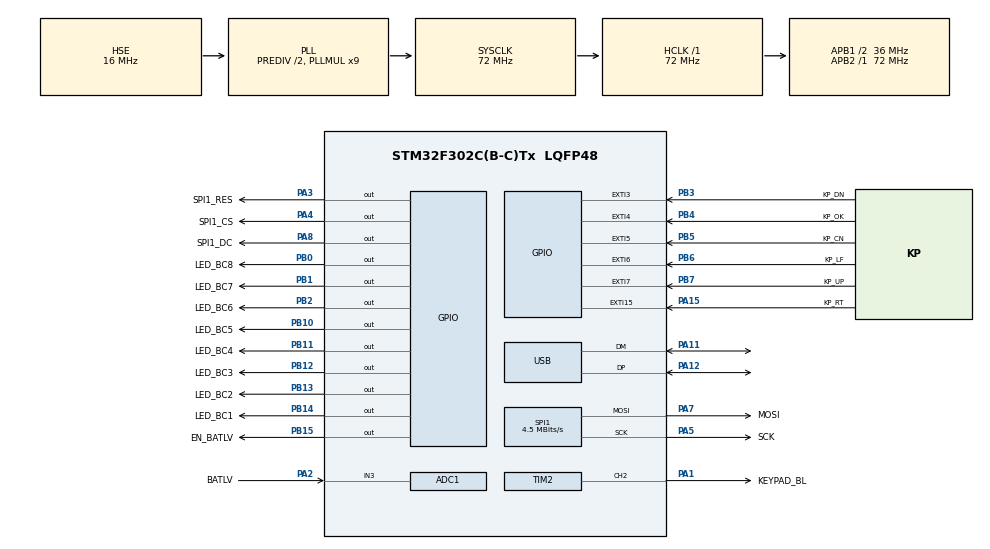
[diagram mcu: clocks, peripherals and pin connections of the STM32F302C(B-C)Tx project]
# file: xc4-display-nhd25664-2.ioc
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ADC1.Channel-1\#ChannelRegularConversion=ADC_CHANNEL_3
ADC1.NbrOfConversionFlag=1
ADC1.Offset-1\#ChannelRegularConversion=0
ADC1.OffsetNumber-1\#ChannelRegularConversion=ADC_OFFSET_NONE
ADC1.Rank-1\#ChannelRegularConversion=1
ADC1.SamplingTime-1\#ChannelRegularConversion=ADC_SAMPLETIME_1CYCLE_5
ADC1.master=1
Mcu.Family=STM32F3
Mcu.Name=STM32F302C(B-C)Tx
Mcu.Package=LQFP48
NVIC.EXTI15_10_IRQn=true\:1\:1\:true\:false\:true\:true\:true\:true
NVIC.EXTI3_IRQn=true\:1\:1\:true\:false\:true\:true\:true\:true
NVIC.EXTI4_IRQn=true\:1\:1\:true\:false\:true\:true\:true\:true
NVIC.EXTI9_5_IRQn=true\:1\:1\:true\:false\:true\:true\:true\:true
NVIC.PriorityGroup=NVIC_PRIORITYGROUP_3
NVIC.RCC_IRQn=true\:1\:0\:true\:false\:true\:true\:false\:true
NVIC.TIM2_IRQn=true\:1\:0\:true\:false\:true\:true\:true\:true
NVIC.TIM3_IRQn=true\:0\:0\:false\:false\:true\:true\:true\:true
NVIC.TIM4_IRQn=true\:0\:0\:false\:false\:true\:true\:true\:true
NVIC.USB_HP_CAN_TX_IRQn=true\:0\:0\:false\:false\:true\:true\:true\:true
NVIC.USB_LP_CAN_RX0_IRQn=true\:0\:1\:false\:false\:true\:true\:true\:true
PA1.GPIO_Label=KEYPAD_BL
PA1.Signal=S_TIM2_CH2
PA11.Mode=Device
PA11.Signal=USB_DM
PA12.Mode=Device
PA12.Signal=USB_DP
PA13.Mode=Serial_Wire
PA13.Signal=SYS_JTMS-SWDIO
PA14.Mode=Serial_Wire
PA14.Signal=SYS_JTCK-SWCLK
PA15.GPIO_Label=KP_RT
PA15.GPIO_ModeDefaultEXTI=GPIO_MODE_IT_FALLING
PA15.GPIO_PuPd=GPIO_PULLUP
PA15.Signal=GPXTI15
PA2.GPIO_Label=BATLV
PA2.Mode=IN3-Single-Ended
PA2.Signal=ADC1_IN3
PA3.GPIO_Label=SPI1_RES
PA3.Signal=GPIO_Output
PA4.GPIO_Label=SPI1_CS
PA4.Signal=GPIO_Output
PA5.GPIO_Label=SCK
PA5.Mode=TX_Only_Simplex_Unidirect_Master
PA5.Signal=SPI1_SCK
PA7.GPIO_Label=MOSI
PA7.Mode=TX_Only_Simplex_Unidirect_Master
PA7.Signal=SPI1_MOSI
PA8.GPIO_Label=SPI1_DC
PA8.Signal=GPIO_Output
PB0.GPIO_Label=LED_BC8
PB0.Signal=GPIO_Output
PB1.GPIO_Label=LED_BC7
PB1.Signal=GPIO_Output
PB10.GPIO_Label=LED_BC5
PB10.Signal=GPIO_Output
PB11.GPIO_Label=LED_BC4
PB11.Signal=GPIO_Output
PB12.GPIO_Label=LED_BC3
PB12.Signal=GPIO_Output
PB13.GPIO_Label=LED_BC2
PB13.Signal=GPIO_Output
PB14.GPIO_Label=LED_BC1
PB14.Signal=GPIO_Output
PB15.GPIO_Label=EN_BATLV
PB15.Signal=GPIO_Output
PB2.GPIO_Label=LED_BC6
PB2.Signal=GPIO_Output
PB3.GPIO_Label=KP_DN
PB3.GPIO_ModeDefaultEXTI=GPIO_MODE_IT_FALLING
PB3.GPIO_PuPd=GPIO_PULLUP
PB3.Signal=GPXTI3
PB4.GPIO_Label=KP_OK
PB4.GPIO_ModeDefaultEXTI=GPIO_MODE_IT_FALLING
PB4.GPIO_PuPd=GPIO_PULLUP
PB4.Signal=GPXTI4
PB5.GPIO_Label=KP_CN
PB5.GPIO_ModeDefaultEXTI=GPIO_MODE_IT_FALLING
PB5.GPIO_PuPd=GPIO_PULLUP
PB5.Signal=GPXTI5
PB6.GPIO_Label=KP_LF
PB6.GPIO_ModeDefaultEXTI=GPIO_MODE_IT_FALLING
PB6.GPIO_PuPd=GPIO_PULLUP
PB6.Signal=GPXTI6
PB7.GPIO_Label=KP_UP
PB7.GPIO_ModeDefaultEXTI=GPIO_MODE_IT_FALLING
PB7.GPIO_PuPd=GPIO_PULLUP
PB7.Signal=GPXTI7
PF0-OSC_IN.Mode=HSE-External-Oscillator
PF0-OSC_IN.Signal=RCC_OSC_IN
PF1-OSC_OUT.Mode=HSE-External-Oscillator
PF1-OSC_OUT.Signal=RCC_OSC_OUT
ProjectManager.HeapSize=0x200
ProjectManager.StackSize=0x400
ProjectManager.TargetToolchain=STM32CubeIDE
RCC.AHBFreq_Value=72000000
RCC.APB1CLKDivider=RCC_HCLK_DIV2
RCC.APB1Freq_Value=36000000
RCC.APB1TimFreq_Value=72000000
RCC.APB2Freq_Value=72000000
RCC.APB2TimFreq_Value=72000000
RCC.CortexFreq_Value=72000000
RCC.HCLKFreq_Value=72000000
RCC.HSE_VALUE=16000000
RCC.HSI_VALUE=8000000
RCC.LSE_VALUE=32768
RCC.PLLMUL=RCC_PLL_MUL9
RCC.PRESCALERUSB=RCC_USBCLKSOURCE_PLL_DIV1_5
RCC.RCC_PLLsource_Clock_Source_FROM_HSE=RCC_HSE_PREDIV_DIV2
RCC.SYSCLKFreq_VALUE=72000000
RCC.SYSCLKSourceVirtual=RCC_SYSCLKSOURCE_PLLCLK
RCC.USBFreq_Value=48000000
SH.S_TIM2_CH2.0=TIM2_CH2,PWM Generation2 CH2
SPI1.BaudRatePrescaler=SPI_BAUDRATEPRESCALER_16
SPI1.CalculateBaudRate=4.5 MBits/s
SPI1.DataSize=SPI_DATASIZE_8BIT
SPI1.Direction=SPI_DIRECTION_2LINES
SPI1.Mode=SPI_MODE_MASTER
SPI1.VirtualType=VM_MASTER
TIM2.AutoReloadPreload=TIM_AUTORELOAD_PRELOAD_ENABLE
TIM2.Channel-PWM\ Generation2\ CH2=TIM_CHANNEL_2
TIM2.Period=65535
TIM2.Prescaler=0
TIM2.Pulse-PWM\ Generation2\ CH2=0
TIM3.Period=30
TIM3.Prescaler=60000
TIM4.Period=64999
TIM4.Prescaler=5499
USB_DEVICE.CLASS_NAME_FS=CDC
USB_DEVICE.MANUFACTURER_STRING=Viacast
USB_DEVICE.PID_CDC_FS=0x2303
USB_DEVICE.PRODUCT_STRING_CDC_FS=USB Nano Display
USB_DEVICE.USBD_SELF_POWERED=0
USB_DEVICE.VID=0x067B
USB_DEVICE.VirtualMode=Cdc
USB_DEVICE.VirtualModeFS=Cdc_FS
VP_TIM2_VS_ClockSourceINT.Mode=Internal
VP_TIM3_VS_ClockSourceINT.Mode=Internal
VP_TIM4_VS_ClockSourceINT.Mode=Internal
VP_USB_DEVICE_VS_USB_DEVICE_CDC_FS.Mode=CDC_FS
board=custom

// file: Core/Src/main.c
/* USER CODE BEGIN Header */
/**
  ******************************************************************************
  * @file           : main.c
  * @brief          : Main program body
  ******************************************************************************
  * @attention
  *
  * Copyright (c) 2022 STMicroelectronics.
  * All rights reserved.
  *
  * This software is licensed under terms that can be found in the LICENSE file
  * in the root directory of this software component.
  * If no LICENSE file comes with this software, it is provided AS-IS.
  *
  ******************************************************************************
  */
/* USER CODE END Header */
#include "main.h"
#include "usb_device.h"

/* USER CODE BEGIN Includes */
#include "ac.h"
/* USER CODE END Includes */

ADC_HandleTypeDef hadc1;

SPI_HandleTypeDef hspi1;

TIM_HandleTypeDef htim2;
TIM_HandleTypeDef htim3;
TIM_HandleTypeDef htim4;

void SystemClock_Config(void);
static void MX_GPIO_Init(void);
static void MX_SPI1_Init(void);
static void MX_ADC1_Init(void);
static void MX_TIM2_Init(void);
static void MX_TIM3_Init(void);
static void MX_TIM4_Init(void);

int main(void)
{

  /* MCU Configuration--------------------------------------------------------*/

  /* Reset of all peripherals, Initializes the Flash interface and the Systick. */
  HAL_Init();

  /* Configure the system clock */
  SystemClock_Config();

  /* Initialize all configured peripherals */
  MX_GPIO_Init();
  MX_SPI1_Init();
  MX_ADC1_Init();
  MX_TIM2_Init();
  MX_USB_DEVICE_Init();
  MX_TIM3_Init();
  MX_TIM4_Init();
  /* USER CODE BEGIN 2 */
  start_app();
  /* USER CODE END 2 */

  /* Infinite loop */
  /* USER CODE BEGIN WHILE */
  while (1)
  {
	  __WFI();
    /* USER CODE END WHILE */

  }
}

void SystemClock_Config(void)
{
  RCC_OscInitTypeDef RCC_OscInitStruct = {0};
  RCC_ClkInitTypeDef RCC_ClkInitStruct = {0};
  RCC_PeriphCLKInitTypeDef PeriphClkInit = {0};

  /** Initializes the RCC Oscillators according to the specified parameters
  * in the RCC_OscInitTypeDef structure.
  */
  RCC_OscInitStruct.OscillatorType = RCC_OSCILLATORTYPE_HSE;
  RCC_OscInitStruct.HSEState = RCC_HSE_ON;
  RCC_OscInitStruct.HSEPredivValue = RCC_HSE_PREDIV_DIV2;
  RCC_OscInitStruct.HSIState = RCC_HSI_ON;
  RCC_OscInitStruct.PLL.PLLState = RCC_PLL_ON;
  RCC_OscInitStruct.PLL.PLLSource = RCC_PLLSOURCE_HSE;
  RCC_OscInitStruct.PLL.PLLMUL = RCC_PLL_MUL9;
  if (HAL_RCC_OscConfig(&RCC_OscInitStruct) != HAL_OK)
  {
    Error_Handler();
  }

  /** Initializes the CPU, AHB and APB buses clocks
  */
  RCC_ClkInitStruct.ClockType = RCC_CLOCKTYPE_HCLK|RCC_CLOCKTYPE_SYSCLK
                              |RCC_CLOCKTYPE_PCLK1|RCC_CLOCKTYPE_PCLK2;
  RCC_ClkInitStruct.SYSCLKSource = RCC_SYSCLKSOURCE_PLLCLK;
  RCC_ClkInitStruct.AHBCLKDivider = RCC_SYSCLK_DIV1;
  RCC_ClkInitStruct.APB1CLKDivider = RCC_HCLK_DIV2;
  RCC_ClkInitStruct.APB2CLKDivider = RCC_HCLK_DIV1;

  if (HAL_RCC_ClockConfig(&RCC_ClkInitStruct, FLASH_LATENCY_2) != HAL_OK)
  {
    Error_Handler();
  }
  PeriphClkInit.PeriphClockSelection = RCC_PERIPHCLK_USB|RCC_PERIPHCLK_ADC12;
  PeriphClkInit.Adc12ClockSelection = RCC_ADC12PLLCLK_DIV1;
  PeriphClkInit.USBClockSelection = RCC_USBCLKSOURCE_PLL_DIV1_5;
  if (HAL_RCCEx_PeriphCLKConfig(&PeriphClkInit) != HAL_OK)
  {
    Error_Handler();
  }
}

static void MX_ADC1_Init(void)
{

  ADC_MultiModeTypeDef multimode = {0};
  ADC_ChannelConfTypeDef sConfig = {0};

  /** Common config
  */
  hadc1.Instance = ADC1;
  hadc1.Init.ClockPrescaler = ADC_CLOCK_ASYNC_DIV1;
  hadc1.Init.Resolution = ADC_RESOLUTION_12B;
  hadc1.Init.ScanConvMode = ADC_SCAN_DISABLE;
  hadc1.Init.ContinuousConvMode = DISABLE;
  hadc1.Init.DiscontinuousConvMode = DISABLE;
  hadc1.Init.ExternalTrigConvEdge = ADC_EXTERNALTRIGCONVEDGE_NONE;
  hadc1.Init.ExternalTrigConv = ADC_SOFTWARE_START;
  hadc1.Init.DataAlign = ADC_DATAALIGN_RIGHT;
  hadc1.Init.NbrOfConversion = 1;
  hadc1.Init.DMAContinuousRequests = DISABLE;
  hadc1.Init.EOCSelection = ADC_EOC_SINGLE_CONV;
  hadc1.Init.LowPowerAutoWait = DISABLE;
  hadc1.Init.Overrun = ADC_OVR_DATA_OVERWRITTEN;
  if (HAL_ADC_Init(&hadc1) != HAL_OK)
  {
    Error_Handler();
  }

  /** Configure the ADC multi-mode
  */
  multimode.Mode = ADC_MODE_INDEPENDENT;
  if (HAL_ADCEx_MultiModeConfigChannel(&hadc1, &multimode) != HAL_OK)
  {
    Error_Handler();
  }

  /** Configure Regular Channel
  */
  sConfig.Channel = ADC_CHANNEL_3;
  sConfig.Rank = ADC_REGULAR_RANK_1;
  sConfig.SingleDiff = ADC_SINGLE_ENDED;
  sConfig.SamplingTime = ADC_SAMPLETIME_1CYCLE_5;
  sConfig.OffsetNumber = ADC_OFFSET_NONE;
  sConfig.Offset = 0;
  if (HAL_ADC_ConfigChannel(&hadc1, &sConfig) != HAL_OK)
  {
    Error_Handler();
  }

}

static void MX_SPI1_Init(void)
{

  /* SPI1 parameter configuration*/
  hspi1.Instance = SPI1;
  hspi1.Init.Mode = SPI_MODE_MASTER;
  hspi1.Init.Direction = SPI_DIRECTION_2LINES;
  hspi1.Init.DataSize = SPI_DATASIZE_8BIT;
  hspi1.Init.CLKPolarity = SPI_POLARITY_LOW;
  hspi1.Init.CLKPhase = SPI_PHASE_1EDGE;
  hspi1.Init.NSS = SPI_NSS_SOFT;
  hspi1.Init.BaudRatePrescaler = SPI_BAUDRATEPRESCALER_16;
  hspi1.Init.FirstBit = SPI_FIRSTBIT_MSB;
  hspi1.Init.TIMode = SPI_TIMODE_DISABLE;
  hspi1.Init.CRCCalculation = SPI_CRCCALCULATION_DISABLE;
  hspi1.Init.CRCPolynomial = 7;
  hspi1.Init.CRCLength = SPI_CRC_LENGTH_DATASIZE;
  hspi1.Init.NSSPMode = SPI_NSS_PULSE_ENABLE;
  if (HAL_SPI_Init(&hspi1) != HAL_OK)
  {
    Error_Handler();
  }

}

static void MX_TIM2_Init(void)
{

  TIM_ClockConfigTypeDef sClockSourceConfig = {0};
  TIM_MasterConfigTypeDef sMasterConfig = {0};
  TIM_OC_InitTypeDef sConfigOC = {0};

  htim2.Instance = TIM2;
  htim2.Init.Prescaler = 0;
  htim2.Init.CounterMode = TIM_COUNTERMODE_UP;
  htim2.Init.Period = 65535;
  htim2.Init.ClockDivision = TIM_CLOCKDIVISION_DIV1;
  htim2.Init.AutoReloadPreload = TIM_AUTORELOAD_PRELOAD_ENABLE;
  if (HAL_TIM_Base_Init(&htim2) != HAL_OK)
  {
    Error_Handler();
  }
  sClockSourceConfig.ClockSource = TIM_CLOCKSOURCE_INTERNAL;
  if (HAL_TIM_ConfigClockSource(&htim2, &sClockSourceConfig) != HAL_OK)
  {
    Error_Handler();
  }
  if (HAL_TIM_PWM_Init(&htim2) != HAL_OK)
  {
    Error_Handler();
  }
  sMasterConfig.MasterOutputTrigger = TIM_TRGO_RESET;
  sMasterConfig.MasterSlaveMode = TIM_MASTERSLAVEMODE_DISABLE;
  if (HAL_TIMEx_MasterConfigSynchronization(&htim2, &sMasterConfig) != HAL_OK)
  {
    Error_Handler();
  }
  sConfigOC.OCMode = TIM_OCMODE_PWM1;
  sConfigOC.Pulse = 0;
  sConfigOC.OCPolarity = TIM_OCPOLARITY_HIGH;
  sConfigOC.OCFastMode = TIM_OCFAST_DISABLE;
  if (HAL_TIM_PWM_ConfigChannel(&htim2, &sConfigOC, TIM_CHANNEL_2) != HAL_OK)
  {
    Error_Handler();
  }
  HAL_TIM_MspPostInit(&htim2);

}

static void MX_TIM3_Init(void)
{

  TIM_ClockConfigTypeDef sClockSourceConfig = {0};
  TIM_MasterConfigTypeDef sMasterConfig = {0};

  htim3.Instance = TIM3;
  htim3.Init.Prescaler = 60000;
  htim3.Init.CounterMode = TIM_COUNTERMODE_UP;
  htim3.Init.Period = 30;
  htim3.Init.ClockDivision = TIM_CLOCKDIVISION_DIV1;
  htim3.Init.AutoReloadPreload = TIM_AUTORELOAD_PRELOAD_DISABLE;
  if (HAL_TIM_Base_Init(&htim3) != HAL_OK)
  {
    Error_Handler();
  }
  sClockSourceConfig.ClockSource = TIM_CLOCKSOURCE_INTERNAL;
  if (HAL_TIM_ConfigClockSource(&htim3, &sClockSourceConfig) != HAL_OK)
  {
    Error_Handler();
  }
  sMasterConfig.MasterOutputTrigger = TIM_TRGO_RESET;
  sMasterConfig.MasterSlaveMode = TIM_MASTERSLAVEMODE_DISABLE;
  if (HAL_TIMEx_MasterConfigSynchronization(&htim3, &sMasterConfig) != HAL_OK)
  {
    Error_Handler();
  }

}

static void MX_TIM4_Init(void)
{

  TIM_ClockConfigTypeDef sClockSourceConfig = {0};
  TIM_MasterConfigTypeDef sMasterConfig = {0};

  htim4.Instance = TIM4;
  htim4.Init.Prescaler = 5499;
  htim4.Init.CounterMode = TIM_COUNTERMODE_UP;
  htim4.Init.Period = 64999;
  htim4.Init.ClockDivision = TIM_CLOCKDIVISION_DIV1;
  htim4.Init.AutoReloadPreload = TIM_AUTORELOAD_PRELOAD_DISABLE;
  if (HAL_TIM_Base_Init(&htim4) != HAL_OK)
  {
    Error_Handler();
  }
  sClockSourceConfig.ClockSource = TIM_CLOCKSOURCE_INTERNAL;
  if (HAL_TIM_ConfigClockSource(&htim4, &sClockSourceConfig) != HAL_OK)
  {
    Error_Handler();
  }
  sMasterConfig.MasterOutputTrigger = TIM_TRGO_RESET;
  sMasterConfig.MasterSlaveMode = TIM_MASTERSLAVEMODE_DISABLE;
  if (HAL_TIMEx_MasterConfigSynchronization(&htim4, &sMasterConfig) != HAL_OK)
  {
    Error_Handler();
  }

}

static void MX_GPIO_Init(void)
{
  GPIO_InitTypeDef GPIO_InitStruct = {0};

  /* GPIO Ports Clock Enable */
  __HAL_RCC_GPIOF_CLK_ENABLE();
  __HAL_RCC_GPIOA_CLK_ENABLE();
  __HAL_RCC_GPIOB_CLK_ENABLE();

  /*Configure GPIO pin Output Level */
  HAL_GPIO_WritePin(GPIOA, SPI1_RES_Pin|SPI1_CS_Pin|SPI1_DC_Pin, GPIO_PIN_RESET);

  /*Configure GPIO pin Output Level */
  HAL_GPIO_WritePin(GPIOB, LED_BC8_Pin|LED_BC7_Pin|LED_BC6_Pin|LED_BC5_Pin
                          |LED_BC4_Pin|LED_BC3_Pin|LED_BC2_Pin|LED_BC1_Pin
                          |EN_BATLV_Pin, GPIO_PIN_RESET);

  /*Configure GPIO pins : SPI1_RES_Pin SPI1_CS_Pin SPI1_DC_Pin */
  GPIO_InitStruct.Pin = SPI1_RES_Pin|SPI1_CS_Pin|SPI1_DC_Pin;
  GPIO_InitStruct.Mode = GPIO_MODE_OUTPUT_PP;
  GPIO_InitStruct.Pull = GPIO_NOPULL;
  GPIO_InitStruct.Speed = GPIO_SPEED_FREQ_LOW;
  HAL_GPIO_Init(GPIOA, &GPIO_InitStruct);

  /*Configure GPIO pins : LED_BC8_Pin LED_BC7_Pin LED_BC6_Pin LED_BC5_Pin
                           LED_BC4_Pin LED_BC3_Pin LED_BC2_Pin LED_BC1_Pin
                           EN_BATLV_Pin */
  GPIO_InitStruct.Pin = LED_BC8_Pin|LED_BC7_Pin|LED_BC6_Pin|LED_BC5_Pin
                          |LED_BC4_Pin|LED_BC3_Pin|LED_BC2_Pin|LED_BC1_Pin
                          |EN_BATLV_Pin;
  GPIO_InitStruct.Mode = GPIO_MODE_OUTPUT_PP;
  GPIO_InitStruct.Pull = GPIO_NOPULL;
  GPIO_InitStruct.Speed = GPIO_SPEED_FREQ_LOW;
  HAL_GPIO_Init(GPIOB, &GPIO_InitStruct);

  /*Configure GPIO pin : KP_RT_Pin */
  GPIO_InitStruct.Pin = KP_RT_Pin;
  GPIO_InitStruct.Mode = GPIO_MODE_IT_FALLING;
  GPIO_InitStruct.Pull = GPIO_PULLUP;
  HAL_GPIO_Init(KP_RT_GPIO_Port, &GPIO_InitStruct);

  /*Configure GPIO pins : KP_DN_Pin KP_OK_Pin KP_CN_Pin KP_LF_Pin
                           KP_UP_Pin */
  GPIO_InitStruct.Pin = KP_DN_Pin|KP_OK_Pin|KP_CN_Pin|KP_LF_Pin
                          |KP_UP_Pin;
  GPIO_InitStruct.Mode = GPIO_MODE_IT_FALLING;
  GPIO_InitStruct.Pull = GPIO_PULLUP;
  HAL_GPIO_Init(GPIOB, &GPIO_InitStruct);

  /* EXTI interrupt init*/
  HAL_NVIC_SetPriority(EXTI3_IRQn, 1, 1);
  HAL_NVIC_EnableIRQ(EXTI3_IRQn);

  HAL_NVIC_SetPriority(EXTI4_IRQn, 1, 1);
  HAL_NVIC_EnableIRQ(EXTI4_IRQn);

  HAL_NVIC_SetPriority(EXTI9_5_IRQn, 1, 1);
  HAL_NVIC_EnableIRQ(EXTI9_5_IRQn);

  HAL_NVIC_SetPriority(EXTI15_10_IRQn, 1, 1);
  HAL_NVIC_EnableIRQ(EXTI15_10_IRQn);

}

void Error_Handler(void)
{
  __disable_irq();
  while (1)
  {
  }
}
